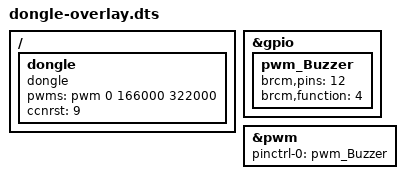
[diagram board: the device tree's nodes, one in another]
/dts-v1/;
/plugin/;

/ {
	fragment@0 {
		target = <&gpio>;
		__overlay__ {
			pwm_Buzzer: pwm_Buzzer {
				brcm,pins = <12>;
				brcm,function = <4>;
			};
		};
	};

	fragment@1 {
		target = <&pwm>;
		__overlay__ {
			pinctrl-names = "default";
			pinctrl-0 = <&pwm_Buzzer>;
			status = "okay";
		};
	};

	fragment@2 {
		target-path = "/";
		__overlay__ {
			dongle {
				compatible = "dongle";
				status = "okay";
				pwms = <&pwm 0 166000 322000>;
				ccnrst = <9>;
			};
		};
	};
};
